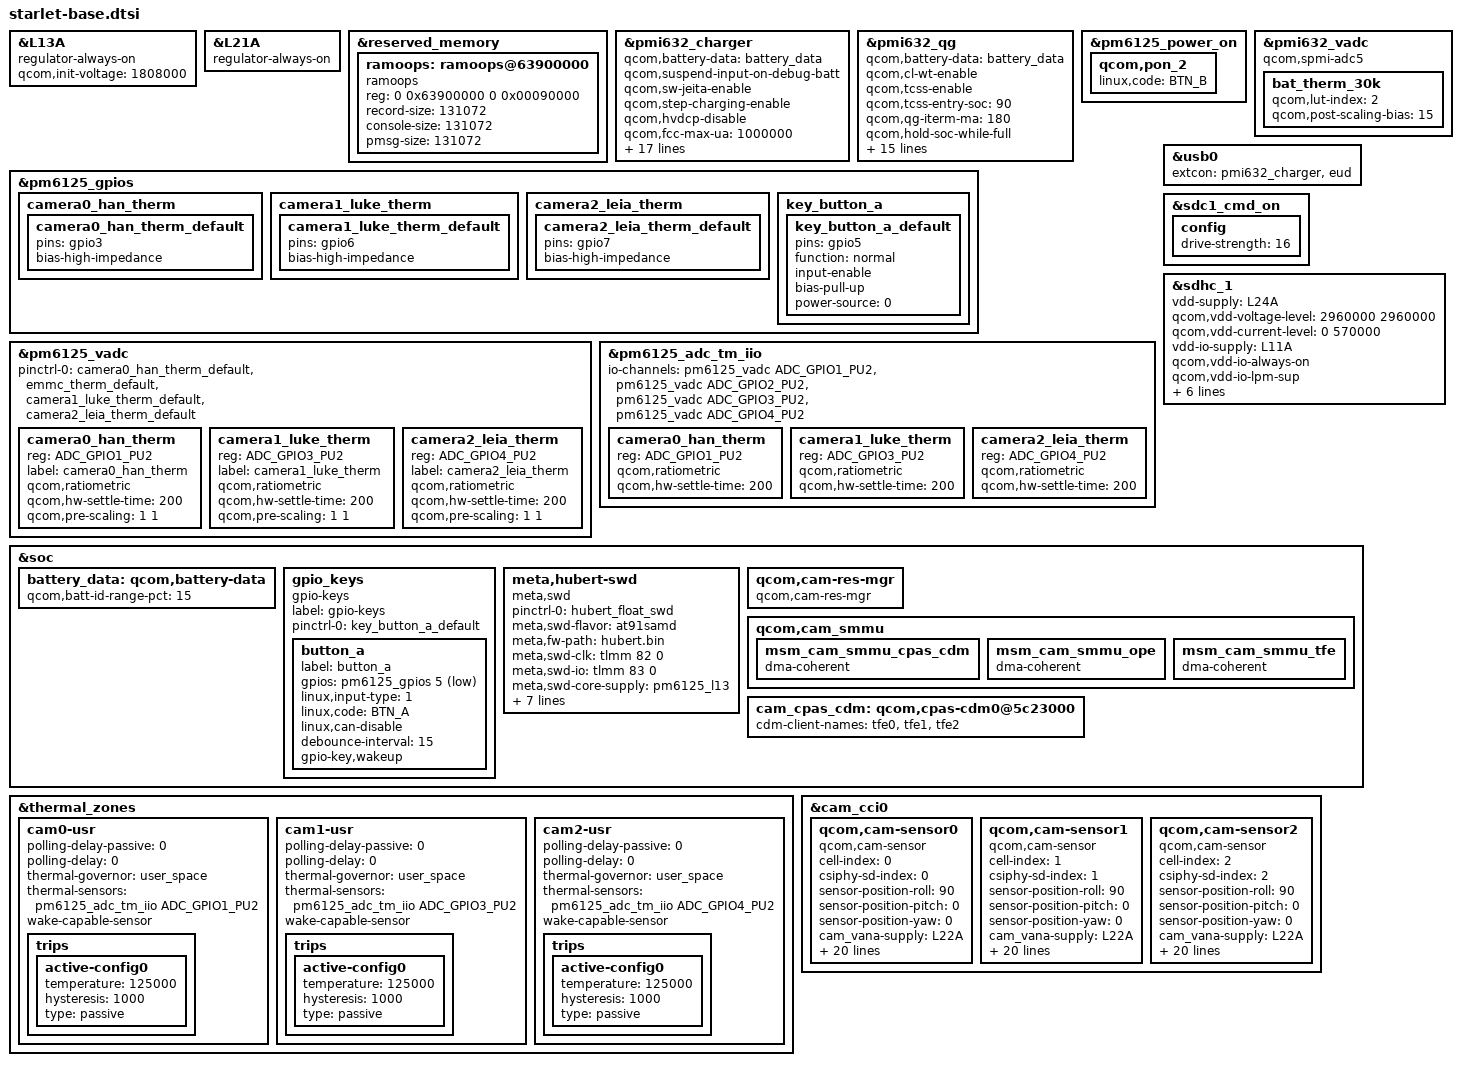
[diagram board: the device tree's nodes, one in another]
#include <dt-bindings/clock/qcom,gcc-bengal.h>
#include <dt-bindings/gpio/gpio.h>
#include <dt-bindings/interrupt-controller/arm-gic.h>
#include <dt-bindings/iio/qcom,spmi-vadc.h>
#include <dt-bindings/input/input.h>
#include "starlet-syncboss.dtsi"
#include "vendor-base/qcom/bengal-thermal-overlay.dtsi"

&L13A {
	// TODO: T69508688: investigate potential for future power savings
	regulator-always-on;
	qcom,init-voltage = <1808000>;
};

&L21A {
	regulator-always-on;
};

&reserved_memory {
	ramoops: ramoops@63900000 {
		compatible = "ramoops";
		reg = <0 0x63900000 0 0x00090000>;
		record-size = <131072>;
		console-size = <131072>;
		pmsg-size = <131072>;
	};
};

&pmi632_charger {
	qcom,battery-data = <&battery_data>;
	qcom,suspend-input-on-debug-batt;
	qcom,sw-jeita-enable;
	qcom,step-charging-enable;
	qcom,hvdcp-disable;
	qcom,fcc-max-ua = <1000000>;
	qcom,fv-max-uv = <4140000>;
	qcom,chg-term-src = <1>;
	qcom,chg-term-current-ma = <(-150)>;
	qcom,wd-bark-time-secs = <128>;
	/* SMB1355 only */
	qcom,sec-charger-config = <0>;
	dpdm-supply = <&qusb_phy0>;
	qcom,charger-temp-max = <800>;
	qcom,smb-temp-max = <800>;
	qcom,auto-recharge-soc = <95>;
	qcom,flash-disable-soc = <10>;
	qcom,suspend-input-on-full-batt;
	qcom,hw-die-temp-mitigation;
	qcom,hw-connector-mitigation;
	qcom,connector-internal-pull-kohm = <100>;
	qcom,float-option = <1>;
	qcom,thermal-mitigation = <3000000 2500000
			2000000 1500000 1000000 500000>;
};

&pmi632_qg {
	qcom,battery-data = <&battery_data>;
	qcom,cl-wt-enable;
	qcom,tcss-enable;
	qcom,tcss-entry-soc = <90>;
	qcom,qg-iterm-ma = <180>;
	qcom,hold-soc-while-full;
	qcom,linearize-soc;
	qcom,qg-use-s7-ocv;
	qcom,debug-batt-id-range = <200000 240000>;
	qcom,s2-acc-interval-ms = <40>;
	qcom,s2-acc-length = <256>;
	qcom,s2-fifo-length = <1>;
	qcom,s3-entry-ibat-ua = <23000>;
	qcom,s3-exit-ibat-ua  = <30000>;
	qcom,vbatt-cutoff-mv = <3400>;
	qcom,vbatt-low-mv = <3500>;
	qcom,vbatt-low-cold-mv = <3800>;
	qcom,vbatt-empty-mv = <3200>;
	qcom,vbatt-empty-cold-mv = <3000>;
	io-channels = <&pmi632_vadc ADC_BAT_THERM_PU1>,
					<&pmi632_vadc ADC_BAT_ID_PU2>;
};

&pm6125_power_on {
	qcom,pon_2 {
		linux,code = <BTN_B>;
	};
};

&pmi632_vadc {
	compatible = "qcom,spmi-adc5";

	/delete-node/i_parallel;
	bat_therm_30k {
		qcom,lut-index = <2>;
		qcom,post-scaling-bias = <15>;
	};
};

&pm6125_gpios {
	camera0_han_therm {
		camera0_han_therm_default: camera0_han_therm_default {
			pins = "gpio3";
			bias-high-impedance;
		};
	};

	camera1_luke_therm {
		camera1_luke_therm_default: camera1_luke_therm_default {
			pins = "gpio6";
			bias-high-impedance;
		};
	};

	camera2_leia_therm {
		camera2_leia_therm_default: camera2_leia_therm_default {
			pins = "gpio7";
			bias-high-impedance;
		};
	};

	key_button_a {
		key_button_a_default: key_button_a_default {
			pins = "gpio5";
			function = "normal";
			input-enable;
			bias-pull-up;
			power-source = <0>;
		};
	};
};

&pm6125_vadc {
	#address-cells = <1>;
	#size-cells = <0>;
	pinctrl-names = "default";
	pinctrl-0 = <&camera0_han_therm_default &emmc_therm_default
			&camera1_luke_therm_default &camera2_leia_therm_default>;

	camera0_han_therm {
		reg = <ADC_GPIO1_PU2>;
		label = "camera0_han_therm ";
		qcom,ratiometric;
		qcom,hw-settle-time = <200>;
		qcom,pre-scaling = <1 1>;
	};

	camera1_luke_therm {
		reg = <ADC_GPIO3_PU2>;
		label = "camera1_luke_therm ";
		qcom,ratiometric;
		qcom,hw-settle-time = <200>;
		qcom,pre-scaling = <1 1>;
	};

	camera2_leia_therm {
		reg = <ADC_GPIO4_PU2>;
		label = "camera2_leia_therm ";
		qcom,ratiometric;
		qcom,hw-settle-time = <200>;
		qcom,pre-scaling = <1 1>;
	};
};

&pm6125_adc_tm_iio {
	io-channels = <&pm6125_vadc ADC_GPIO1_PU2>,
			<&pm6125_vadc ADC_GPIO2_PU2>,
			<&pm6125_vadc ADC_GPIO3_PU2>,
			<&pm6125_vadc ADC_GPIO4_PU2>;

	camera0_han_therm {
		reg = <ADC_GPIO1_PU2>;
		qcom,ratiometric;
		qcom,hw-settle-time = <200>;
	};

	camera1_luke_therm {
		reg = <ADC_GPIO3_PU2>;
		qcom,ratiometric;
		qcom,hw-settle-time = <200>;
	};

	camera2_leia_therm {
		reg = <ADC_GPIO4_PU2>;
		qcom,ratiometric;
		qcom,hw-settle-time = <200>;
	};
};

&usb0 {
	extcon = <&pmi632_charger>, <&eud>;
};

&sdc1_cmd_on {
	config {
		drive-strength = <16>; /* 16 MA */
	};
};

&sdhc_1 {
	vdd-supply = <&L24A>;
	qcom,vdd-voltage-level = <2960000 2960000>;
	qcom,vdd-current-level = <0 570000>;

	vdd-io-supply = <&L11A>;
	qcom,vdd-io-always-on;
	qcom,vdd-io-lpm-sup;
	qcom,vdd-io-voltage-level = <1800000 1800000>;
	qcom,vdd-io-current-level = <0 325000>;

	pinctrl-names = "active", "sleep";
	pinctrl-0 = <&sdc1_clk_on &sdc1_cmd_on &sdc1_data_on
					&sdc1_rclk_on>;
	pinctrl-1 = <&sdc1_clk_off &sdc1_cmd_off &sdc1_data_off
					&sdc1_rclk_off>;

	status = "ok";
};

&soc {
	battery_data: qcom,battery-data {
		qcom,batt-id-range-pct = <15>;
		#include "qg-batterydata-starlet-SCUD-100K-3200mAH-PMI632.dtsi"
		#include "qg-batterydata-starlet-SCUD-200K-3200mAH-PMI632.dtsi"
	};

	gpio_keys {
		compatible = "gpio-keys";
		label = "gpio-keys";

		pinctrl-names = "default";
		pinctrl-0 = <&key_button_a_default>;

		button_a {
			label = "button_a";
			gpios = <&pm6125_gpios 5 GPIO_ACTIVE_LOW>;
			linux,input-type = <1>;
			linux,code = <BTN_A>;
			linux,can-disable;
			debounce-interval = <15>;
			gpio-key,wakeup;
		};
	};

	meta,hubert-swd {
		compatible = "meta,swd";

		pinctrl-names = "default";
		pinctrl-0 = <&hubert_float_swd>;

		meta,swd-flavor = "at91samd";
		meta,fw-path = "hubert.bin";
		meta,swd-clk = <&tlmm 82 0>;
		meta,swd-io  = <&tlmm 83 0>;
		meta,swd-core-supply = <&pm6125_l13>;
		meta,swd-core-voltage-level = <1808000 1808000>;
		meta,flash-block-size = <256>;
		meta,flash-page-size = <64>;
		meta,flash-page-count = <2048>;
		meta,flash-page-bootloader-protected-count = <0>;
		meta,flash-page-retained-count = <64>;

		meta,swd-provisioning;
	};

	qcom,cam-res-mgr {
		compatible = "qcom,cam-res-mgr";
		status = "ok";
	};

	qcom,cam_smmu {
		msm_cam_smmu_cpas_cdm {
			dma-coherent;
		};

		msm_cam_smmu_ope {
			dma-coherent;
		};

		msm_cam_smmu_tfe {
			dma-coherent;
		};
	};

	cam_cpas_cdm: qcom,cpas-cdm0@5c23000 {
		cdm-client-names = "tfe0", "tfe1", "tfe2";
	};
};

&thermal_zones {
	cam0-usr {
		/* Han ("In") */
		polling-delay-passive = <0>;
		polling-delay = <0>;
		thermal-governor = "user_space";
		thermal-sensors = <&pm6125_adc_tm_iio ADC_GPIO1_PU2>;
		wake-capable-sensor;
		trips {
			active-config0 {
				temperature = <125000>;
				hysteresis = <1000>;
				type = "passive";
			};
		};
	};

	cam1-usr {
		/* Luke ("Out") */
		polling-delay-passive = <0>;
		polling-delay = <0>;
		thermal-governor = "user_space";
		thermal-sensors = <&pm6125_adc_tm_iio ADC_GPIO3_PU2>;
		wake-capable-sensor;
		trips {
			active-config0 {
				temperature = <125000>;
				hysteresis = <1000>;
				type = "passive";
			};
		};
	};

	cam2-usr {
		/* Leia ("Up") */
		polling-delay-passive = <0>;
		polling-delay = <0>;
		thermal-governor = "user_space";
		thermal-sensors = <&pm6125_adc_tm_iio ADC_GPIO4_PU2>;
		wake-capable-sensor;
		trips {
			active-config0 {
				temperature = <125000>;
				hysteresis = <1000>;
				type = "passive";
			};
		};
	};

	/delete-node/pmi632-ibat-lvl0;
	/delete-node/pmi632-ibat-lvl1;
	/delete-node/pmi632-vbat-lvl0;
	/delete-node/pmi632-vbat-lvl1;
	/delete-node/pmi632-vbat-lvl2;
	/delete-node/pmi632-bcl-lvl0;
	/delete-node/pmi632-bcl-lvl1;
	/delete-node/pmi632-bcl-lvl2;
	/delete-node/soc;
};

&cam_cci0 {
	qcom,cam-sensor0 {
		cell-index = <0>;
		compatible = "qcom,cam-sensor";
		csiphy-sd-index = <0>;
		sensor-position-roll = <90>;
		sensor-position-pitch = <0>;
		sensor-position-yaw = <0>;
		cam_vana-supply = <&L22A>;
		cam_vio-supply = <&L14A>;
		cam_clk-supply = <&gcc_camss_top_gdsc>;
		regulator-names = "cam_vana", "cam_vio", "cam_clk";
		rgltr-cntrl-support;
		pwm-switch;
		rgltr-min-voltage = <2960000 1800000 0>;
		rgltr-max-voltage = <2960000 1800000 0>;
		rgltr-load-current = <120000 80000 0>;
		gpio-no-mux = <0>;
		pinctrl-names = "cam_default", "cam_suspend";
		pinctrl-0 = <&cam_sensor_mclk0_active>;
		pinctrl-1 = <&cam_sensor_mclk0_suspend>;
		gpios = <&tlmm 20 0>;
		gpio-req-tbl-num = <0>;
		gpio-req-tbl-flags = <1>;
		gpio-req-tbl-label = "CAMIF_MCLK0";
		sensor-mode = <0>;
		cci-master = <0>;
		status = "ok";
		clocks = <&gcc GCC_CAMSS_MCLK0_CLK>;
		clock-names = "cam_clk";
		clock-cntl-level = "turbo";
		clock-rates = <19200000>;
	};

	qcom,cam-sensor1 {
		cell-index = <1>;
		compatible = "qcom,cam-sensor";
		csiphy-sd-index = <1>;
		sensor-position-roll = <90>;
		sensor-position-pitch = <0>;
		sensor-position-yaw = <0>;
		cam_vana-supply = <&L22A>;
		cam_vio-supply = <&L14A>;
		cam_clk-supply = <&gcc_camss_top_gdsc>;
		regulator-names = "cam_vana", "cam_vio", "cam_clk";
		rgltr-cntrl-support;
		pwm-switch;
		rgltr-min-voltage = <2960000 1800000 0>;
		rgltr-max-voltage = <2960000 1800000 0>;
		rgltr-load-current = <120000 80000 0>;
		gpio-no-mux = <0>;
		pinctrl-names = "cam_default", "cam_suspend";
		pinctrl-0 = <&cam_sensor_mclk1_active>;
		pinctrl-1 = <&cam_sensor_mclk1_suspend>;
		gpios = <&tlmm 21 0>;
		gpio-req-tbl-num = <0>;
		gpio-req-tbl-flags = <1>;
		gpio-req-tbl-label = "CAMIF_MCLK1";
		sensor-mode = <0>;
		cci-master = <0>;
		status = "ok";
		clocks = <&gcc GCC_CAMSS_MCLK1_CLK>;
		clock-names = "cam_clk";
		clock-cntl-level = "turbo";
		clock-rates = <19200000>;
	};

	qcom,cam-sensor2 {
		cell-index = <2>;
		compatible = "qcom,cam-sensor";
		csiphy-sd-index = <2>;
		sensor-position-roll = <90>;
		sensor-position-pitch = <0>;
		sensor-position-yaw = <0>;
		cam_vana-supply = <&L22A>;
		cam_vio-supply = <&L14A>;
		cam_clk-supply = <&gcc_camss_top_gdsc>;
		regulator-names = "cam_vana", "cam_vio", "cam_clk";
		rgltr-cntrl-support;
		pwm-switch;
		rgltr-min-voltage = <2960000 1800000 0>;
		rgltr-max-voltage = <2960000 1800000 0>;
		rgltr-load-current = <120000 80000 0>;
		gpio-no-mux = <0>;
		pinctrl-names = "cam_default", "cam_suspend";
		pinctrl-0 = <&cam_sensor_mclk2_active>;
		pinctrl-1 = <&cam_sensor_mclk2_suspend>;
		gpios = <&tlmm 27 0>;
		gpio-req-tbl-num = <0>;
		gpio-req-tbl-flags = <1>;
		gpio-req-tbl-label = "CAMIF_MCLK2";
		sensor-mode = <0>;
		cci-master = <0>;
		status = "ok";
		clocks = <&gcc GCC_CAMSS_MCLK2_CLK>;
		clock-names = "cam_clk";
		clock-cntl-level = "turbo";
		clock-rates = <19200000>;
	};
};
